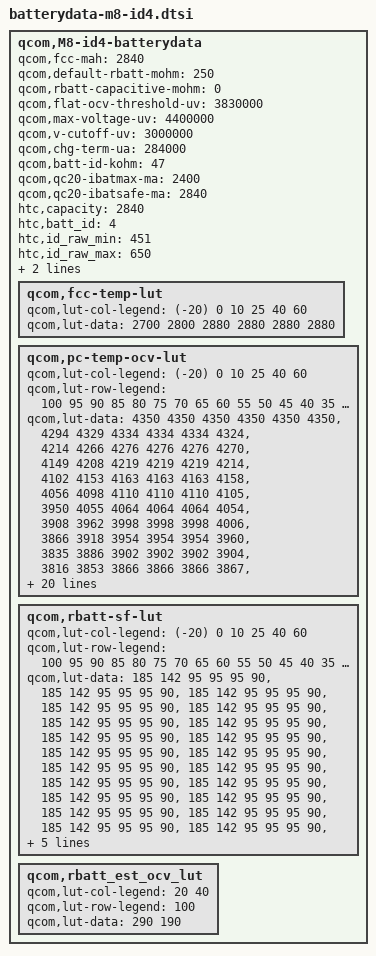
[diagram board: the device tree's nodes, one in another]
	qcom,M8-id4-batterydata {
	qcom,fcc-mah = <2840>;
	qcom,default-rbatt-mohm = <250>;
	qcom,rbatt-capacitive-mohm = <0>;
	qcom,flat-ocv-threshold-uv = <3830000>;
	qcom,max-voltage-uv = <4400000>;
	qcom,v-cutoff-uv = <3000000>;
	qcom,chg-term-ua = <284000>;
	qcom,batt-id-kohm = <47>;
	qcom,qc20-ibatmax-ma = <2400>;
	qcom,qc20-ibatsafe-ma = <2840>;
	htc,capacity = <2840>;
	htc,batt_id = <4>;
	htc,id_raw_min = <451>;
	htc,id_raw_max = <650>;
	htc,type = <1>;
	htc,model_name = "B0P6B100";

	qcom,fcc-temp-lut {
		qcom,lut-col-legend = <(-20) 0 10 25 40 60>;
		qcom,lut-data = <2700 2800 2880 2880 2880 2880>;
	};

	qcom,pc-temp-ocv-lut {
		qcom,lut-col-legend = <(-20) 0 10 25 40 60>;
		qcom,lut-row-legend = <100 95 90 85 80 75 70 65 60 55 50 45 40 35 30 25 20 16 13 11 10 9 8 7 6 5 4 3 2 1 0>;
		qcom,lut-data = <4350 4350 4350 4350 4350 4350>,
				<4294 4329 4334 4334 4334 4324>,
				<4214 4266 4276 4276 4276 4270>,
				<4149 4208 4219 4219 4219 4214>,
				<4102 4153 4163 4163 4163 4158>,
				<4056 4098 4110 4110 4110 4105>,
				<3950 4055 4064 4064 4064 4054>,
				<3908 3962 3998 3998 3998 4006>,
				<3866 3918 3954 3954 3954 3960>,
				<3835 3886 3902 3902 3902 3904>,
				<3816 3853 3866 3866 3866 3867>,
				<3798 3825 3838 3838 3838 3840>, 
				<3784 3800 3814 3814 3814 3816>,
				<3768 3782 3796 3796 3796 3794>,
				<3753 3769 3778 3778 3778 3770>,
				<3738 3754 3762 3762 3762 3742>,
				<3720 3734 3738 3738 3738 3716>,
				<3704 3716 3708 3708 3708 3686>,
				<3686 3705 3692 3692 3692 3671>,
				<3674 3698 3690 3690 3690 3670>,
				<3664 3693 3688 3688 3688 3668>,
				<3655 3688 3686 3686 3686 3668>,
				<3644 3681 3684 3684 3684 3664>,
				<3629 3669 3680 3680 3680 3654>,
				<3610 3651 3662 3662 3662 3628>,
				<3586 3624 3624 3624 3624 3587>,
				<3550 3584 3572 3572 3572 3536>,
				<3500 3526 3506 3506 3506 3470>,
				<3426 3444 3418 3418 3418 3382>,
                                                <3302 3308 3284 3284 3284 3246>,
                                                <3000 3000 3000 3000 3000 3000>;
	};

	qcom,rbatt-sf-lut {
		qcom,lut-col-legend = <(-20) 0 10 25 40 60>;
		qcom,lut-row-legend = <100 95 90 85 80 75 70 65 60 55 50 45 40 35 30 25 20 16 13 11 10 9 8 7 6 5 4 3 2 1>;
		qcom,lut-data = <185 142 95 95 95 90>,
				<185 142 95 95 95 90>,
				<185 142 95 95 95 90>,
				<185 142 95 95 95 90>,
				<185 142 95 95 95 90>,
				<185 142 95 95 95 90>,
				<185 142 95 95 95 90>,
				<185 142 95 95 95 90>,
				<185 142 95 95 95 90>,
				<185 142 95 95 95 90>,
				<185 142 95 95 95 90>,
				<185 142 95 95 95 90>,
				<185 142 95 95 95 90>,
				<185 142 95 95 95 90>,
				<185 142 95 95 95 90>,
				<185 142 95 95 95 90>,
				<185 142 95 95 95 90>,
				<185 142 95 95 95 90>,
				<185 142 95 95 95 90>,
				<185 142 95 95 95 90>,
				<185 142 95 95 95 90>,
				<185 142 95 95 95 90>,
				<185 142 95 95 95 90>,
				<185 142 95 95 95 90>,
				<185 142 95 95 95 90>,
				<185 142 95 95 95 90>,
                                                <185 142 95 95 95 90>,
	                                    <185 142 95 95 95 90>,
				<185 142 95 95 95 90>,
				<185 142 95 95 95 90>;
		};

	qcom,rbatt_est_ocv_lut {
		qcom,lut-col-legend = <20 40>;
		qcom,lut-row-legend = <100>;
		qcom,lut-data = <290 190>;
		};
	};
